# GD32F4xx register map
File version: 1.0
CPU: CM4 r0p1, little endian, MPU, FPU, 4 interrupt priority bits
Registers are 32-bit, read-write, reset 0x0 unless marked. A register's access mark holds for its fields unless they carry their own. Offsets are from the block's base; [hi:lo] are bit positions; {n}, {i} and the like mark numbered series; 'fields as' and 'values as' point back to an identical list.

## EXMC — External memory controller
Base 0xA0000000
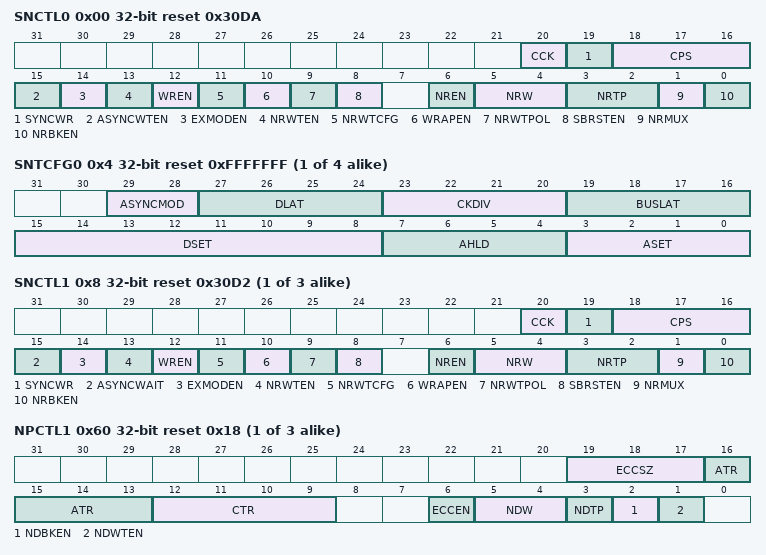
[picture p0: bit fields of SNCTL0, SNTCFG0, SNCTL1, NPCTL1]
0x00 SNCTL0 reset 0x30DA — SRAM/NOR flash control register 0
  [20] CCK — Consecutive Clock
  [19] SYNCWR — Synchronous write
  [18:16] CPS — CRAM page size
  [15] ASYNCWTEN — Asynchronous wait enable
  [14] EXMODEN — Extended mode enable
  [13] NRWTEN — NWAIT signal enable
  [12] WREN — Write enable
  [11] NRWTCFG — NWAIT signal configuration, only work in synchronous mode
  [10] WRAPEN — Wrapped burst mode enable
  [9] NRWTPOL — NWAIT signal polarity
  [8] SBRSTEN — Synchronous burst enable
  [6] NREN — NOR Flash access enable
  [5:4] NRW — NOR bank memory data bus width
  [3:2] NRTP — NOR bank memory type
  [1] NRMUX — NOR bank memory address/data multiplexing
  [0] NRBKEN — NOR bank enable
{0x4+8i} SNTCFG{i} reset 0xFFFFFFF (i=0..3) — SRAM/NOR flash timing configuration register {i}
  [29:28] ASYNCMOD — Asynchronous access mode
  [27:24] DLAT — Data latency for NOR Flash
  [23:20] CKDIV — Synchronous clock divide ratio
  [19:16] BUSLAT — Bus latency
  [15:8] DSET — Data setup time
  [7:4] AHLD — Address hold time
  [3:0] ASET — Address setup time
{0x0+8i} SNCTL{i} reset 0x30D2 (i=1..3) — SRAM/NOR flash control register {i}
  [20] CCK — Consecutive Clock
  [19] SYNCWR — Synchronous write
  [18:16] CPS — CRAM page size
  [15] ASYNCWAIT — Asynchronous wait
  [14] EXMODEN — Extended mode enable
  [13] NRWTEN — NWAIT signal enable
  [12] WREN — Write enable
  [11] NRWTCFG — NWAIT signal configuration, only work in synchronous mode
  [10] WRAPEN — Wrapped burst mode enable
  [9] NRWTPOL — NWAIT signal polarity
  [8] SBRSTEN — Synchronous burst enable
  [6] NREN — NOR Flash access enable
  [5:4] NRW — NOR bank memory data bus width
  [3:2] NRTP — NOR bank memory type
  [1] NRMUX — NOR bank memory address/data multiplexing
  [0] NRBKEN — NOR bank enable
{0x40+0x20*i} NPCTL{i} reset 0x18 (i=1..3) — NAND flash/PC card control register {i}
  [19:17] ECCSZ — ECC size
  [16:13] ATR — ALE to RE delay
  [12:9] CTR — CLE to RE delay
  [6] ECCEN — ECC enable
  [5:4] NDW — NAND bank memory data bus width
  [3] NDTP — NAND bank memory type
  [2] NDBKEN — NAND bank enable
  [1] NDWTEN — Wait feature enable
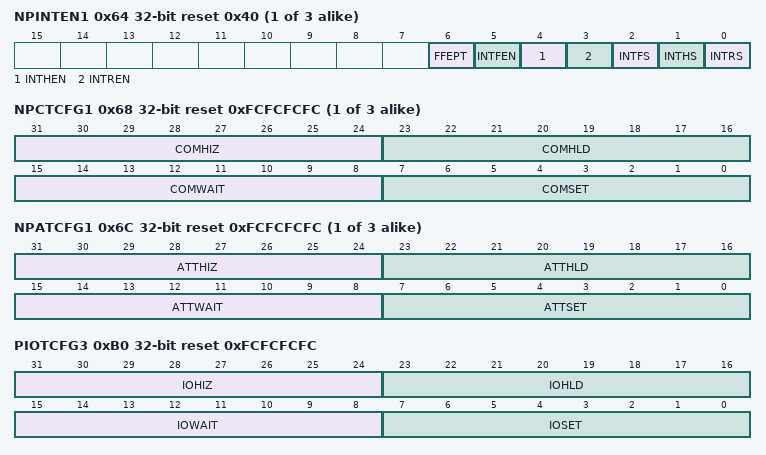
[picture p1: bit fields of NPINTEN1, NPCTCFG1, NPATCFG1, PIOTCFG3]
{0x44+0x20*i} NPINTEN{i} reset 0x40 (i=1..3) — NAND flash/PC card interrupt enable register {i}
  [6] FFEPT — FIFO empty flag
  [5] INTFEN — Interrupt falling edge detection enable
  [4] INTHEN — Interrupt high-level detection enable
  [3] INTREN — Interrupt rising edge detection enable bit
  [2] INTFS — Interrupt falling edge status
  [1] INTHS — Interrupt high-level status
  [0] INTRS — Interrupt rising edge status
{0x48+0x20*i} NPCTCFG{i} reset 0xFCFCFCFC (i=1..3) — NAND flash/PC card common space timing configuration register {i}
  [31:24] COMHIZ — Common memory data bus HiZ time
  [23:16] COMHLD — Common memory hold time
  [15:8] COMWAIT — Common memory wait time
  [7:0] COMSET — Common memory setup time
{0x4C+0x20*i} NPATCFG{i} reset 0xFCFCFCFC (i=1..3) — NAND flash/PC card attribute space timing configuration register {i}
  [31:24] ATTHIZ — Attribute memory data bus HiZ time
  [23:16] ATTHLD — Attribute memory hold time
  [15:8] ATTWAIT — Attribute memory wait time
  [7:0] ATTSET — Attribute memory setup time
0x74 NECC1 ro — NAND flash ECC register 1
  [31:0] ECC — ECC result
0x94 NECC2 ro — NAND flash ECC register 2
  [31:0] ECC — ECC result
0xB0 PIOTCFG3 reset 0xFCFCFCFC — PC card I/O space timing configuration register
  [31:24] IOHIZ — IO space data bus HiZ time
  [23:16] IOHLD — IO space hold time
  [15:8] IOWAIT — IO space wait time
  [7:0] IOSET — IO space setup time
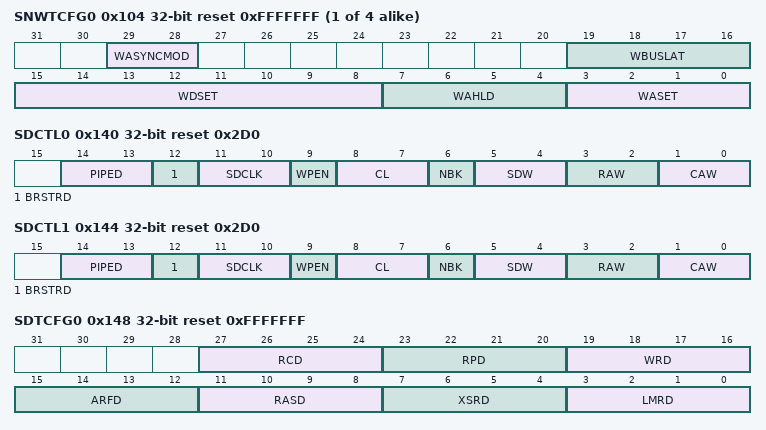
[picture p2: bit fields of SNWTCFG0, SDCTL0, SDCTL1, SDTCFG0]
{0x104+8i} SNWTCFG{i} reset 0xFFFFFFF (i=0..3) — SRAM/NOR flash write timing configuration register {i}
  [29:28] WASYNCMOD — Asynchronous access mode
  [19:16] WBUSLAT — Bus latency
  [15:8] WDSET — Data setup time
  [7:4] WAHLD — Address hold time
  [3:0] WASET — Address setup time
0x140 SDCTL0 reset 0x2D0 — SDRAM control register 0
  [14:13] PIPED — Pipeline delay
  [12] BRSTRD — Burst read
  [11:10] SDCLK — SDRAM clock configuration
  [9] WPEN — Write protection enable
  [8:7] CL — CAS Latency
  [6] NBK — Number of banks
  [5:4] SDW — SDRAM data bus width
  [3:2] RAW — Row address bit width
  [1:0] CAW — Column address bit width
0x144 SDCTL1 reset 0x2D0 — SDRAM control register 1
  fields as SDCTL0
0x148 SDTCFG0 reset 0xFFFFFFF — SDRAM timing configuration register 0
  [27:24] RCD — Row to column delay
  [23:20] RPD — Row precharge delay
  [19:16] WRD — Write recovery delay
  [15:12] ARFD — Auto refresh delay
  [11:8] RASD — Row address select delay
  [7:4] XSRD — Exit Self-refresh delay
  [3:0] LMRD — Load Mode Register Delay
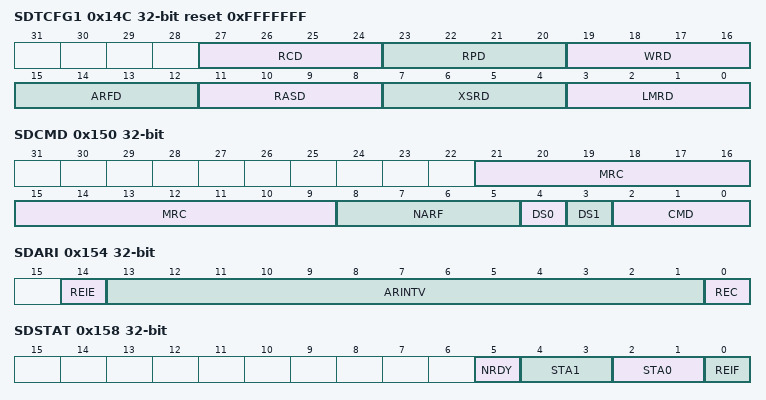
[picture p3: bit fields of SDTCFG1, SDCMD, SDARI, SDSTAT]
0x14C SDTCFG1 reset 0xFFFFFFF — SDRAM timing configuration register 1
  fields as SDTCFG0
0x150 SDCMD — SDRAM command register
  [21:9] MRC — Mode register content
  [8:5] NARF — Number of successive Auto-refresh
  [4] DS0 — Device select 0
  [3] DS1 — Device select 1
  [2:0] CMD — Command
0x154 SDARI — SDRAM auto-refresh interval register
  [14] REIE — Refresh error interrupt Enable
  [13:1] ARINTV — Auto-Refresh Interval
  [0] REC — Refresh error flag clear
0x158 SDSTAT — SDRAM status register
  [5] NRDY — Not Ready status
  [4:3] STA1 — Device1 status
  [2:1] STA0 — Device 0 status
  [0] REIF — Refresh error interrupt flag
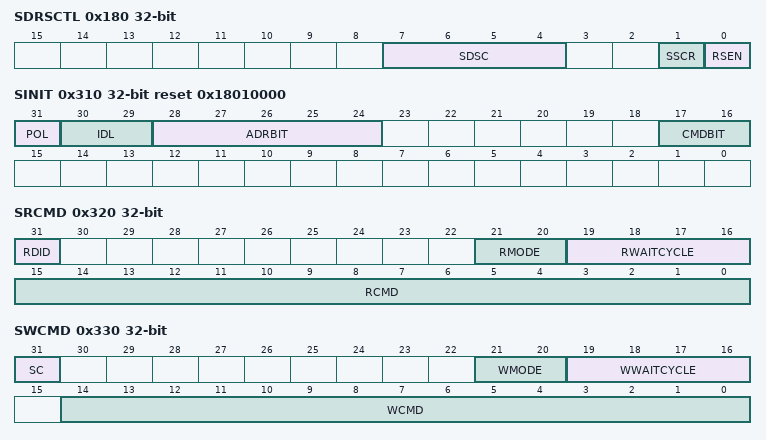
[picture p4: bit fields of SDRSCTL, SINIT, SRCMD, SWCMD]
0x180 SDRSCTL — SDRAM read sample control register
  [7:4] SDSC — Select the delayed sample clock of read data
  [1] SSCR — Select sample cycle of read data
  [0] RSEN — Read sample enable
0x310 SINIT reset 0x18010000 — SPI initialization register
  [31] POL — Read data sample polarity
  [30:29] IDL — SPI PSRAM ID Length
  [28:24] ADRBIT — Bit number of SPI PSRAM address phase
  [17:16] CMDBIT — Bit number of SPI PSRAM command phase
0x320 SRCMD — SPI read command register
  [31] RDID — Send SPI Read ID Command
  [21:20] RMODE — SPI PSRAM Read command mode
  [19:16] RWAITCYCLE — SPI Read Wait Cycle number after address phase
  [15:0] RCMD — SPI Read Command for AHB read transfer
0x330 SWCMD — SPI write command register
  [31] SC — Send SPI Special Command which does not have address and data phase, command code and mode come from WCMD and WMODE
  [21:20] WMODE — SPI PSRAM Write command mode
  [19:16] WWAITCYCLE — SPI Write Wait Cycle number after address phase
  [14:0] WCMD — SPI Write Command for AHB write transfer
0x340 SIDL — SPI ID low register
  [31:0] SIDL — ID Low Data saved for SPI Read ID Command
0x350 SIDH — SPI ID high register
  [31:0] SIDH — ID High Data saved for SPI Read ID Command
